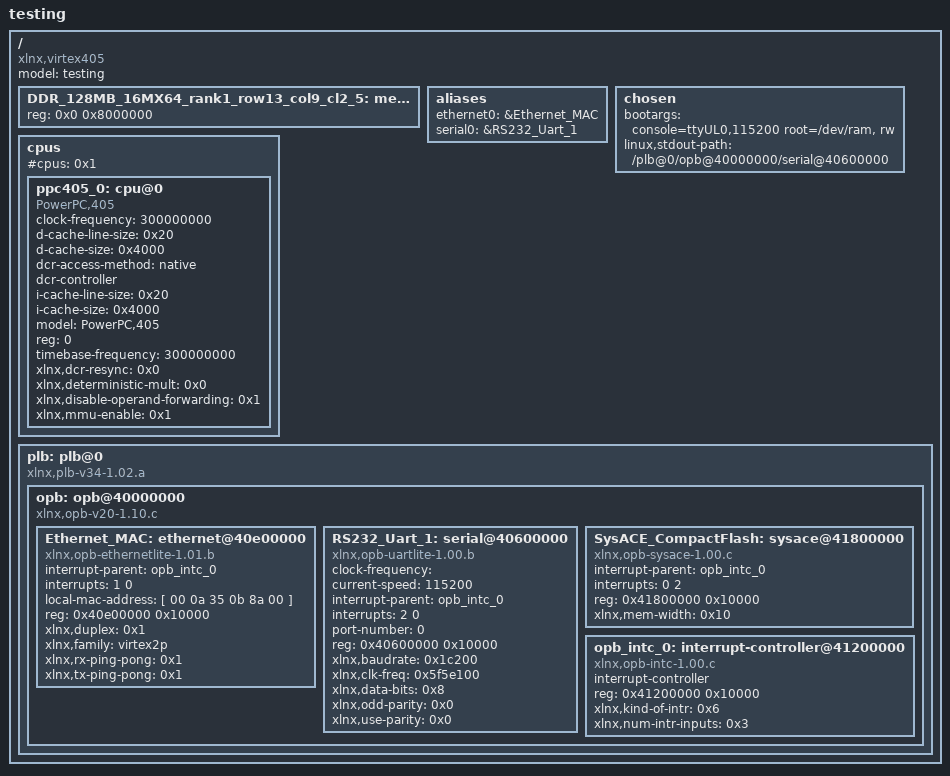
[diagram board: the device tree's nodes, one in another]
/*
 * Device Tree Generator version: 1.3
 *
 * (C) Copyright 2007-2008 Xilinx, Inc.
 * (C) Copyright 2007-2009 Michal Simek
 *
 * Michal SIMEK <monstr@monstr.eu>
 *
 * This program is free software; you can redistribute it and/or
 * modify it under the terms of the GNU General Public License as
 * published by the Free Software Foundation; either version 2 of
 * the License, or (at your option) any later version.
 *
 * This program is distributed in the hope that it will be useful,
 * but WITHOUT ANY WARRANTY; without even the implied warranty of
 * MERCHANTABILITY or FITNESS FOR A PARTICULAR PURPOSE. See the
 * GNU General Public License for more details.
 *
 * You should have received a copy of the GNU General Public License
 * along with this program; if not, write to the Free Software
 * Foundation, Inc., 59 Temple Place, Suite 330, Boston,
 * MA 02111-1307 USA
 *
 * CAUTION: This file is automatically generated by libgen.
 * Version: Xilinx EDK 8.2.02 EDK_Im_Sp2.4
 *
 * XPS project directory: XUPV2P-MicheAngelo
 */

/dts-v1/;
/ {
	#address-cells = <1>;
	#size-cells = <1>;
	compatible = "xlnx,virtex405", "xlnx,virtex";
	model = "testing";
	DDR_128MB_16MX64_rank1_row13_col9_cl2_5: memory@0 {
		device_type = "memory";
		reg = < 0x0 0x8000000 >;
	} ;
	aliases {
		ethernet0 = &Ethernet_MAC;
		serial0 = &RS232_Uart_1;
	} ;
	chosen {
		bootargs = "console=ttyUL0,115200 root=/dev/ram, rw";
		linux,stdout-path = "/plb@0/opb@40000000/serial@40600000";
	} ;
	cpus {
		#address-cells = <1>;
		#cpus = <0x1>;
		#size-cells = <0>;
		ppc405_0: cpu@0 {
			clock-frequency = <300000000>;
			compatible = "PowerPC,405", "ibm,ppc405";
			d-cache-line-size = <0x20>;
			d-cache-size = <0x4000>;
			dcr-access-method = "native";
			dcr-controller ;
			device_type = "cpu";
			i-cache-line-size = <0x20>;
			i-cache-size = <0x4000>;
			model = "PowerPC,405";
			reg = <0>;
			timebase-frequency = <300000000>;
			xlnx,dcr-resync = <0x0>;
			xlnx,deterministic-mult = <0x0>;
			xlnx,disable-operand-forwarding = <0x1>;
			xlnx,mmu-enable = <0x1>;
		} ;
	} ;
	plb: plb@0 {
		#address-cells = <1>;
		#size-cells = <1>;
		compatible = "xlnx,plb-v34-1.02.a", "simple-bus";
		ranges ;
		opb: opb@40000000 {
			#address-cells = <1>;
			#size-cells = <1>;
			compatible = "xlnx,opb-v20-1.10.c", "simple-bus";
			ranges = < 0x40000000 0x40000000 0x40000000 >;
			Ethernet_MAC: ethernet@40e00000 {
				compatible = "xlnx,opb-ethernetlite-1.01.b";
				device_type = "network";
				interrupt-parent = <&opb_intc_0>;
				interrupts = < 1 0 >;
				local-mac-address = [ 00 0a 35 0b 8a 00 ];
				reg = < 0x40e00000 0x10000 >;
				xlnx,duplex = <0x1>;
				xlnx,family = "virtex2p";
				xlnx,rx-ping-pong = <0x1>;
				xlnx,tx-ping-pong = <0x1>;
			} ;
			RS232_Uart_1: serial@40600000 {
				clock-frequency = "";
				compatible = "xlnx,opb-uartlite-1.00.b";
				current-speed = <115200>;
				device_type = "serial";
				interrupt-parent = <&opb_intc_0>;
				interrupts = < 2 0 >;
				port-number = <0>;
				reg = < 0x40600000 0x10000 >;
				xlnx,baudrate = <0x1c200>;
				xlnx,clk-freq = <0x5f5e100>;
				xlnx,data-bits = <0x8>;
				xlnx,odd-parity = <0x0>;
				xlnx,use-parity = <0x0>;
			} ;
			SysACE_CompactFlash: sysace@41800000 {
				compatible = "xlnx,opb-sysace-1.00.c";
				interrupt-parent = <&opb_intc_0>;
				interrupts = < 0 2 >;
				reg = < 0x41800000 0x10000 >;
				xlnx,mem-width = <0x10>;
			} ;
			opb_intc_0: interrupt-controller@41200000 {
				#interrupt-cells = <0x2>;
				compatible = "xlnx,opb-intc-1.00.c", "xlnx,xps-intc-1.00.a";
				interrupt-controller ;
				reg = < 0x41200000 0x10000 >;
				xlnx,kind-of-intr = <0x6>;
				xlnx,num-intr-inputs = <0x3>;
			} ;
		} ;
	} ;
} ;
